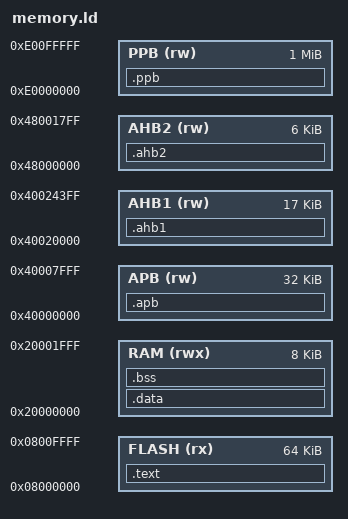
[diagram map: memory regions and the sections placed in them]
/*
 * Copyright (C) 2020 xent
 * Project is distributed under the terms of the GNU General Public License v3.0
 */

ENTRY(RESET_ISR)
EXTERN(vectorTable)

MEMORY
{
  FLASH (rx) : ORIGIN = 0x08000000, LENGTH = 64K
  RAM (rwx)  : ORIGIN = 0x20000000, LENGTH = 8K

  APB (rw)   : ORIGIN = 0x40000000, LENGTH = 32K
  AHB1 (rw)  : ORIGIN = 0x40020000, LENGTH = 17K
  AHB2 (rw)  : ORIGIN = 0x48000000, LENGTH = 6K
  PPB (rw)   : ORIGIN = 0xE0000000, LENGTH = 1M
}

SECTIONS
{
  .text : ALIGN(4)
  {
    _stext = .;

    *(.vectors)
    *(.text)
    *(.text*)
    *(.rodata)
    *(.rodata*)

    _etext = .;

    . = ALIGN(4);
    _sidata = .;
  } >FLASH =0xFF

  .data : AT(_sidata) ALIGN(4)
  {
    _sdata = .;

    *(.data)
    *(.data*)

    _edata = .;
  } >RAM

  .bss : ALIGN(4)
  {
    _sbss = .;

    *(.bss)
    *(.bss*)
    *(COMMON)

    _ebss = .;

    . = ALIGN(4);
    heapStart = .;
  } >RAM

  .apb :
  {
    APB_DOMAIN = .;
  } >APB

  .ahb1 :
  {
    AHB1_DOMAIN = .;
  } >AHB1

  .ahb2 :
  {
    AHB2_DOMAIN = .;
  } >AHB2

  .ppb :
  {
    PPB_DOMAIN = .;
  } >PPB

  /DISCARD/ :
  {
    *(.init)
    *(.fini)

    *(.ARM.exidx*)
    *(.gnu.linkonce.armexidx.*)

    *(.ARM.extab*)
    *(.gnu.linkonce.armextab.*)
  }

  PROVIDE(end = heapStart);
  PROVIDE(_stack = ORIGIN(RAM) + LENGTH(RAM));
}
